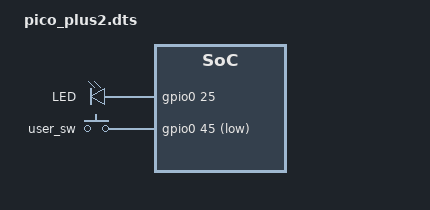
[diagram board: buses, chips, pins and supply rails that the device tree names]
/*
 * Copyright (c) 2024 TOKITA Hiroshi
 *
 * SPDX-License-Identifier: Apache-2.0
 */

/dts-v1/;

#include <zephyr/dt-bindings/input/input-event-codes.h>
#include "pico_plus2-common.dtsi"

/ {
	leds {
		compatible = "gpio-leds";
		led0: led_0 {
			gpios = <&gpio0 25 GPIO_ACTIVE_HIGH>;
			label = "LED";
		};
	};

	pwm_leds {
		compatible = "pwm-leds";
		status = "disabled";
		pwm_led0: pwm_led_0 {
			pwms = <&pwm 9 PWM_MSEC(20) PWM_POLARITY_NORMAL>;
			label = "PWM_LED";
		};
	};

	buttons {
		compatible = "gpio-keys";
		user_sw: user_sw {
			gpios = <&gpio0 45 (GPIO_ACTIVE_LOW)>;
			zephyr,code = <INPUT_KEY_0>;
		};
	};

	aliases {
		led0 = &led0;
		pwm-led0 = &pwm_led0;
		sw0 = &user_sw;
	};
};
